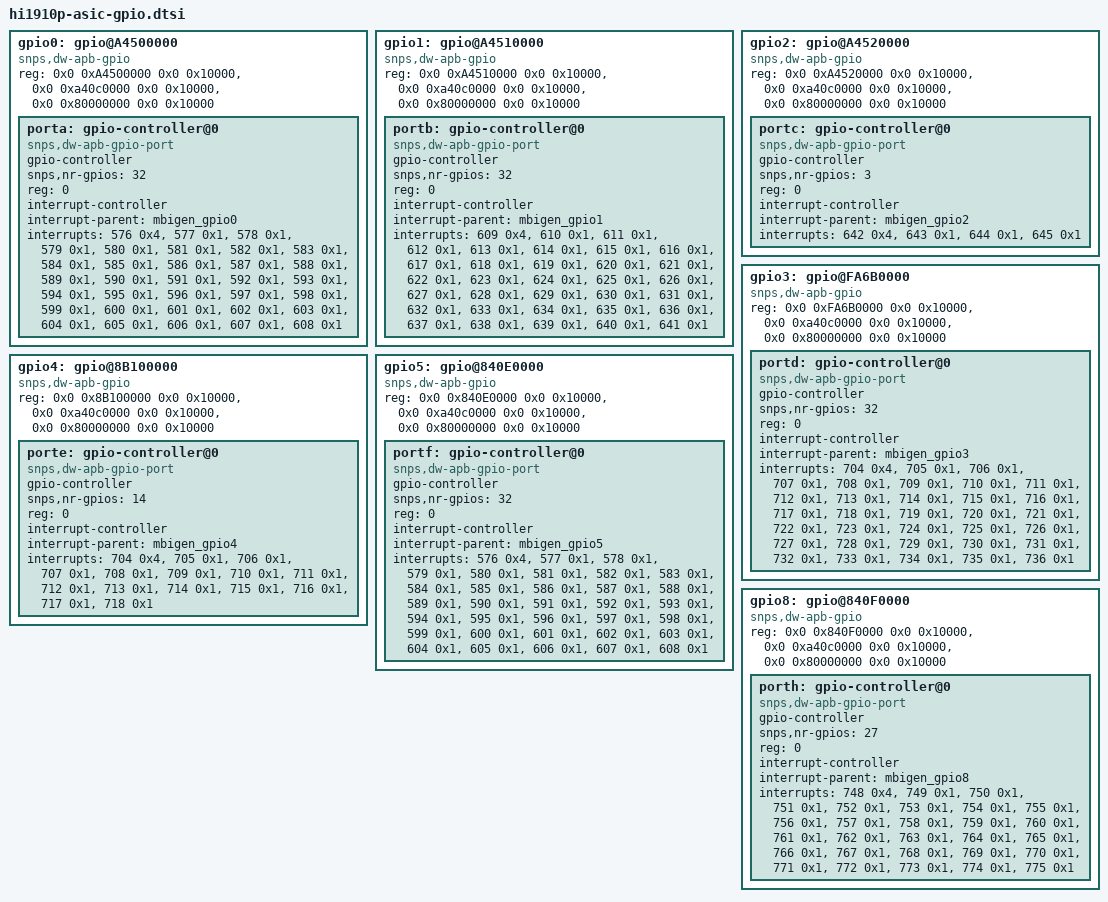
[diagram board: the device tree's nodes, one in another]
	gpio0: gpio@A4500000 {
		compatible = "snps,dw-apb-gpio";
		reg = <0x0 0xA4500000 0x0 0x10000>,
			 <0x0 0xa40c0000 0x0 0x10000>,
			 <0x0 0x80000000 0x0 0x10000>;
		#address-cells = <1>;
		#size-cells = <0>;

		porta: gpio-controller@0 {
			compatible = "snps,dw-apb-gpio-port";
			gpio-controller;
			#gpio-cells = <2>;
			snps,nr-gpios = <32>;
			reg = <0>;
			interrupt-controller;
			interrupt-parent = <&mbigen_gpio0>;
			interrupts = <576 0x4>, <577 0x1>, <578 0x1>, <579 0x1>, <580 0x1>, <581 0x1>,
					<582 0x1>, <583 0x1>, <584 0x1>, <585 0x1>, <586 0x1>, <587 0x1>,
					<588 0x1>, <589 0x1>, <590 0x1>, <591 0x1>, <592 0x1>, <593 0x1>,
					<594 0x1>, <595 0x1>, <596 0x1>, <597 0x1>, <598 0x1>, <599 0x1>,
					<600 0x1>, <601 0x1>, <602 0x1>, <603 0x1>, <604 0x1>, <605 0x1>,
					<606 0x1>, <607 0x1>, <608 0x1>;
			status = "ok";
		};
	};

	gpio1: gpio@A4510000 {
		compatible = "snps,dw-apb-gpio";
		reg = <0x0 0xA4510000 0x0 0x10000>,
			 <0x0 0xa40c0000 0x0 0x10000>,
			 <0x0 0x80000000 0x0 0x10000>;
		#address-cells = <1>;
		#size-cells = <0>;

		portb: gpio-controller@0 {
			compatible = "snps,dw-apb-gpio-port";
			gpio-controller;
			#gpio-cells = <2>;
			snps,nr-gpios = <32>;
			reg = <0>;
			interrupt-controller;
			interrupt-parent = <&mbigen_gpio1>;
			interrupts = <609 0x4>, <610 0x1>, <611 0x1>, <612 0x1>, <613 0x1>, <614 0x1>,
					<615 0x1>, <616 0x1>, <617 0x1>, <618 0x1>, <619 0x1>, <620 0x1>,
					<621 0x1>, <622 0x1>, <623 0x1>, <624 0x1>, <625 0x1>, <626 0x1>,
					<627 0x1>, <628 0x1>, <629 0x1>, <630 0x1>, <631 0x1>, <632 0x1>,
					<633 0x1>, <634 0x1>, <635 0x1>, <636 0x1>, <637 0x1>, <638 0x1>,
					<639 0x1>, <640 0x1>, <641 0x1>;
			status = "ok";
		};
	};

	gpio2: gpio@A4520000 {
		compatible = "snps,dw-apb-gpio";
		reg = <0x0 0xA4520000 0x0 0x10000>,
			 <0x0 0xa40c0000 0x0 0x10000>,
			 <0x0 0x80000000 0x0 0x10000>;
		#address-cells = <1>;
		#size-cells = <0>;

		portc: gpio-controller@0 {
			compatible = "snps,dw-apb-gpio-port";
			gpio-controller;
			#gpio-cells = <2>;
			snps,nr-gpios = <3>;
			reg = <0>;
			interrupt-controller;
			interrupt-parent = <&mbigen_gpio2>;
			interrupts = <642 0x4>, <643 0x1>, <644 0x1>, <645 0x1>;
			status = "ok";
		};
	};

	gpio3: gpio@FA6B0000 {
		compatible = "snps,dw-apb-gpio";
		reg = <0x0 0xFA6B0000 0x0 0x10000>,
			 <0x0 0xa40c0000 0x0 0x10000>,
			 <0x0 0x80000000 0x0 0x10000>;
		#address-cells = <1>;
		#size-cells = <0>;

		portd: gpio-controller@0 {
			compatible = "snps,dw-apb-gpio-port";
			gpio-controller;
			#gpio-cells = <2>;
			snps,nr-gpios = <32>;
			reg = <0>;
			interrupt-controller;
			interrupt-parent = <&mbigen_gpio3>;
			interrupts = <704 0x4>, <705 0x1>, <706 0x1>, <707 0x1>, <708 0x1>, <709 0x1>,
					<710 0x1>, <711 0x1>, <712 0x1>, <713 0x1>, <714 0x1>, <715 0x1>,
					<716 0x1>, <717 0x1>, <718 0x1>, <719 0x1>, <720 0x1>, <721 0x1>,
					<722 0x1>, <723 0x1>, <724 0x1>, <725 0x1>, <726 0x1>, <727 0x1>,
					<728 0x1>, <729 0x1>, <730 0x1>, <731 0x1>, <732 0x1>, <733 0x1>,
					<734 0x1>, <735 0x1>, <736 0x1>;
			status = "ok";
		};
	};

	gpio4: gpio@8B100000 {
		compatible = "snps,dw-apb-gpio";
		reg = <0x0 0x8B100000 0x0 0x10000>,
			 <0x0 0xa40c0000 0x0 0x10000>,
			 <0x0 0x80000000 0x0 0x10000>;
		#address-cells = <1>;
		#size-cells = <0>;

		porte: gpio-controller@0 {
			compatible = "snps,dw-apb-gpio-port";
			gpio-controller;
			#gpio-cells = <2>;
			snps,nr-gpios = <14>;
			reg = <0>;
			interrupt-controller;
			interrupt-parent = <&mbigen_gpio4>;
			interrupts = <704 0x4>, <705 0x1>, <706 0x1>, <707 0x1>, <708 0x1>, <709 0x1>,
					<710 0x1>, <711 0x1>, <712 0x1>, <713 0x1>, <714 0x1>, <715 0x1>,
					<716 0x1>, <717 0x1>, <718 0x1>;
			status = "ok";
		};
	};

	gpio5: gpio@840E0000 {
		compatible = "snps,dw-apb-gpio";
		reg = <0x0 0x840E0000 0x0 0x10000>,
			 <0x0 0xa40c0000 0x0 0x10000>,
			 <0x0 0x80000000 0x0 0x10000>;
		#address-cells = <1>;
		#size-cells = <0>;

		portf: gpio-controller@0 {
			compatible = "snps,dw-apb-gpio-port";
			gpio-controller;
			#gpio-cells = <2>;
			snps,nr-gpios = <32>;
			reg = <0>;
			interrupt-controller;
			interrupt-parent = <&mbigen_gpio5>;
			interrupts = <576 0x4>, <577 0x1>, <578 0x1>, <579 0x1>, <580 0x1>, <581 0x1>,
					<582 0x1>, <583 0x1>, <584 0x1>, <585 0x1>, <586 0x1>, <587 0x1>,
					<588 0x1>, <589 0x1>, <590 0x1>, <591 0x1>, <592 0x1>, <593 0x1>,
					<594 0x1>, <595 0x1>, <596 0x1>, <597 0x1>, <598 0x1>, <599 0x1>,
					<600 0x1>, <601 0x1>, <602 0x1>, <603 0x1>, <604 0x1>, <605 0x1>,
					<606 0x1>, <607 0x1>, <608 0x1>;
			status = "ok";
		};
	};

	gpio8: gpio@840F0000 {
		compatible = "snps,dw-apb-gpio";
		reg = <0x0 0x840F0000 0x0 0x10000>,
			 <0x0 0xa40c0000 0x0 0x10000>,
			 <0x0 0x80000000 0x0 0x10000>;
		#address-cells = <1>;
		#size-cells = <0>;

		porth: gpio-controller@0 {
			compatible = "snps,dw-apb-gpio-port";
			gpio-controller;
			#gpio-cells = <2>;
			snps,nr-gpios = <27>;
			reg = <0>;
			interrupt-controller;
			interrupt-parent = <&mbigen_gpio8>;
			interrupts = <748 0x4>, <749 0x1>, <750 0x1>, <751 0x1>, <752 0x1>, <753 0x1>,
					<754 0x1>, <755 0x1>, <756 0x1>, <757 0x1>, <758 0x1>, <759 0x1>,
					<760 0x1>, <761 0x1>, <762 0x1>, <763 0x1>, <764 0x1>, <765 0x1>,
					<766 0x1>, <767 0x1>, <768 0x1>, <769 0x1>, <770 0x1>, <771 0x1>,
					<772 0x1>, <773 0x1>, <774 0x1>, <775 0x1>;
			status = "ok";
		};
	};
